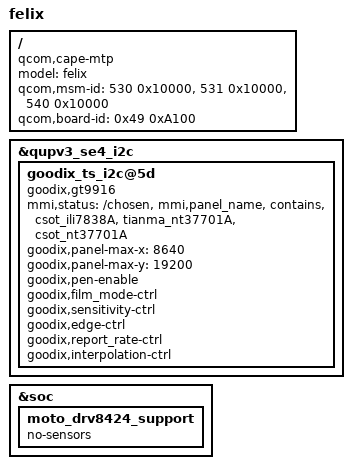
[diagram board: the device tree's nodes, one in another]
/* Copyright (c) 2022, The Linux Foundation. All rights reserved.
 *
 * This program is free software; you can redistribute it and/or modify
 * it under the terms of the GNU General Public License version 2 and
 * only version 2 as published by the Free Software Foundation.
 *
 * This program is distributed in the hope that it will be useful,
 * but WITHOUT ANY WARRANTY; without even the implied warranty of
 * MERCHANTABILITY or FITNESS FOR A PARTICULAR PURPOSE.  See the
 * GNU General Public License for more details.
 */

/dts-v1/;
/plugin/;

#include "cape-felix-common-overlay.dtsi"

/ {
	model = "felix";
	compatible = "qcom,cape-mtp", "qcom,cape", "qcom,mtp", "moto,felix";
	qcom,msm-id = <530 0x10000>, <531 0x10000>, <540 0x10000>;
	qcom,board-id = <0x49 0xA100>;
};

&qupv3_se4_i2c {
	/* Rogue panel */
	goodix_ts_i2c@5d {
		compatible = "goodix,gt9916";
		mmi,status = "/chosen","mmi,panel_name","contains","csot_ili7838A","tianma_nt37701A", "csot_nt37701A";
		goodix,panel-max-x = <8640>;
		goodix,panel-max-y = <19200>;
		goodix,pen-enable;
		goodix,film_mode-ctrl;
		goodix,sensitivity-ctrl;
		goodix,edge-ctrl;
		goodix,report_rate-ctrl;
		goodix,interpolation-ctrl;
	};
};

&soc {
	moto_drv8424_support {
		no-sensors;
	};
};
